AUTOSAR XML (schema 4-2-2)
package /Components
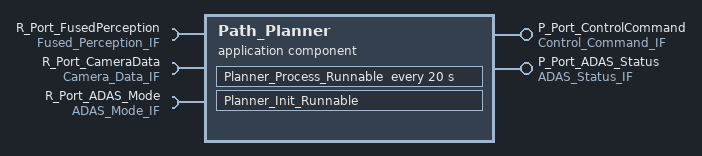
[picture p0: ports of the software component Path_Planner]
  application sw component type Path_Planner
    provide port P_Port_ControlCommand: provided-interface=Control_Command_IF
    provide port P_Port_ADAS_Status: provided-interface=ADAS_Status_IF
    require port R_Port_FusedPerception: required-interface=Fused_Perception_IF
    require port R_Port_CameraData: required-interface=Camera_Data_IF
    require port R_Port_ADAS_Mode: required-interface=ADAS_Mode_IF
    behavior Path_Planner_InternalBehavior
      init event Planner_Init_Event: start-on-event=Planner_Init_Runnable
      swc mode switch event Planner_Mode_Switch_Event: start-on-event=Planner_Process_Runnable, activation=ON-TRANSITION
        mode:
          ADAS_ModeGroup.R_Port_ADAS_Mode.ACC_Mode
          ADAS_ModeGroup.R_Port_ADAS_Mode.LKA_Mode
          ADAS_ModeGroup.R_Port_ADAS_Mode.AEB_Mode
      timing event Planner_Process_Event: start-on-event=Planner_Process_Runnable, period=20
      runnable Planner_Init_Runnable: symbol=Planner_Init
        parameter access PA_Init_Longitudinal_Params: accessed-parameter=R_Port_FusedPerception.Longitudinal_Command
        parameter access PA_Init_Lateral_Params: accessed-parameter=R_Port_CameraData.Lateral_Command
      runnable Planner_Process_Runnable: minimum-start-interval=20, symbol=Planner_Process
        data-receive-point-by-arguments:
          access VA_Recv_Fused_ObjectList: accessed-variable=R_Port_FusedPerception.Fused_ObjectList
          access VA_Recv_Ego_State: accessed-variable=R_Port_FusedPerception.Ego_State
          access VA_Recv_Camera_LaneModel: accessed-variable=R_Port_CameraData.Camera_LaneModel
        data-send-points:
          5 x access:
            VA_Send_Longitudinal_Command: accessed-variable=P_Port_ControlCommand.Longitudinal_Command
            VA_Send_Lateral_Command: accessed-variable=P_Port_ControlCommand.Lateral_Command
            VA_Send_ACC_Status: accessed-variable=P_Port_ADAS_Status.ACC_Status
            VA_Send_LKA_Status: accessed-variable=P_Port_ADAS_Status.LKA_Status
            VA_Send_AEB_Status: accessed-variable=P_Port_ADAS_Status.AEB_Status
        parameter access PA_Run_Ego_Params: accessed-parameter=R_Port_FusedPerception.Ego_State
        parameter access PA_Run_LaneModel_Params: accessed-parameter=R_Port_CameraData.Camera_LaneModel
